VERSION "2.0"

NS_ :

BS_:

BU_: PCU NDR

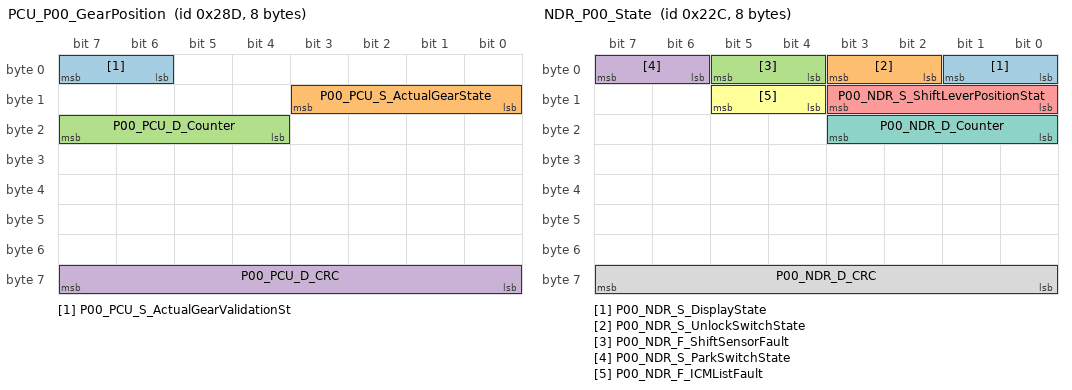
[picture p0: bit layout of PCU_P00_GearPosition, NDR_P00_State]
BO_ 653 PCU_P00_GearPosition: 8 PCU
 SG_ P00_PCU_S_ActualGearValidationSt : 6|2@1+ (1,0) [0|3] ""  PCU
 SG_ P00_PCU_S_ActualGearState : 8|4@1+ (1,0) [0|15] ""  PCU
 SG_ P00_PCU_D_Counter : 20|4@1+ (1,0) [0|15] ""  PCU
 SG_ P00_PCU_D_CRC : 56|8@1+ (1,0) [0|255] ""  PCU

BO_ 556 NDR_P00_State: 8 NDR
 SG_ P00_NDR_S_DisplayState : 0|2@1+ (1,0) [0|3] ""  NDR
 SG_ P00_NDR_S_UnlockSwitchState : 2|2@1+ (1,0) [0|3] ""  NDR
 SG_ P00_NDR_F_ShiftSensorFault : 4|2@1+ (1,0) [0|3] ""  NDR
 SG_ P00_NDR_S_ParkSwitchState : 6|2@1+ (1,0) [0|3] ""  NDR
 SG_ P00_NDR_S_ShiftLeverPositionStat : 8|4@1+ (1,0) [0|15] ""  NDR
 SG_ P00_NDR_F_ICMListFault : 12|2@1+ (1,0) [0|1] ""  NDR
 SG_ P00_NDR_D_Counter : 16|4@1+ (1,0) [0|15] ""  NDR
 SG_ P00_NDR_D_CRC : 56|8@1+ (1,0) [0|255] ""  NDR

BO_ 1174 PCU_P01_Authentication: 8 PCU
 SG_ P01_PCU_S_AuthenticationState : 0|8@1+ (1,0) [0|3] ""  PCU

CM_ BO_ 653 "Gear Position Message; Functional Type";
CM_ SG_ 653 P00_PCU_S_ActualGearValidationSt "Actual gear validation state";
CM_ SG_ 653 P00_PCU_S_ActualGearState "Actual gear position state";
CM_ SG_ 653 P00_PCU_D_Counter "Up counter (0-15)";
CM_ SG_ 653 P00_PCU_D_CRC "Message CRC for Integrity";
CM_ BO_ 556 "State Message to NDR; Functional Type";
CM_ SG_ 556 P00_NDR_S_DisplayState "Gear position display state";
CM_ SG_ 556 P00_NDR_S_UnlockSwitchState "Unlock switch state";
CM_ SG_ 556 P00_NDR_F_ShiftSensorFault "Shift sensor fault";
CM_ SG_ 556 P00_NDR_S_ParkSwitchState "Park switch state";
CM_ SG_ 556 P00_NDR_S_ShiftLeverPositionStat "Shift lever position state";
CM_ SG_ 556 P00_NDR_F_ICMListFault "Integrated Control Module (ICM) list fault";
CM_ SG_ 556 P00_NDR_D_Counter "Up counter (0-15)";
CM_ SG_ 556 P00_NDR_D_CRC "8 bit CRC";
CM_ BO_ 1174 "Authentication Message; Event Triggered";
CM_ SG_ 1174 P01_PCU_S_AuthenticationState "Authentication state";
BA_DEF_ BO_  "TXRX" ENUM  "TX","RX";
BA_DEF_ BO_  "J1939PgAppearanceOnBus" ENUM  "Default","CAN_Extended","CANFD_Extended";
BA_DEF_ BO_  "J1939CPgSendTimeout" INT -1 3600000;
BA_DEF_ BO_  "J1939CPgTOS" INT 0 7;
BA_DEF_ BU_  "J1939MultiPgSendTimeout" INT 0 3600000;
BA_DEF_ BU_  "J1939MultiPgSizeThreshold" INT 0 64;
BA_DEF_ BU_  "J1939MultiPgBroadcastType" ENUM  "FBFF","FEFF";
BA_DEF_ SG_  "SigType" ENUM  "Default","Range","RangeSigned","ASCII","Discrete","Control","ReferencePGN","DTC","StringDelimiter","StringLength","StringLengthControl","MessageCounter","MessageChecksum";
BA_DEF_ SG_  "GenSigILSupport" ENUM  "No","Yes";
BA_DEF_ SG_  "GenSigSendType" ENUM  "Cyclic","OnWrite","OnWriteWithRepetition","OnChange","OnChangeWithRepetition","IfActive","IfActiveWithRepetition","NoSigSendType";
BA_DEF_ SG_  "GenSigStartValue" INT 0 2147483647;
BA_DEF_ BO_  "GenMsgILSupport" ENUM  "No","Yes";
BA_DEF_ BU_  "NmStationAddress" INT 0 255;
BA_DEF_ BO_  "GenMsgSendType" ENUM  "cyclic","NotUsed","NotUsed","NotUsed","NotUsed","NotUsed","NotUsed","IfActive","noMsgSendType";
BA_DEF_ BO_  "GenMsgRequestable" INT 0 1;
BA_DEF_ BO_  "GenMsgCycleTime" INT 0 3600000;
BA_DEF_ SG_  "SPN" INT 0 524287;
BA_DEF_  "DBName" STRING ;
BA_DEF_  "BusType" STRING ;
BA_DEF_  "ProtocolType" STRING ;
BA_DEF_ BO_  "VFrameFormat" ENUM  "StandardCAN","ExtendedCAN","reserved","J1939PG","reserved","reserved","reserved","reserved","reserved","reserved","reserved","reserved","reserved","reserved","StandardCAN_FD","ExtendedCAN_FD";
BA_DEF_ SG_  "SystemSignalLongSymbol" STRING ;
BA_DEF_DEF_  "TXRX" "TX";
BA_DEF_DEF_  "J1939PgAppearanceOnBus" "Default";
BA_DEF_DEF_  "J1939CPgSendTimeout" -1;
BA_DEF_DEF_  "J1939CPgTOS" 2;
BA_DEF_DEF_  "J1939MultiPgSendTimeout" 2;
BA_DEF_DEF_  "J1939MultiPgSizeThreshold" 56;
BA_DEF_DEF_  "J1939MultiPgBroadcastType" "FBFF";
BA_DEF_DEF_  "SigType" "Default";
BA_DEF_DEF_  "GenSigILSupport" "Yes";
BA_DEF_DEF_  "GenSigSendType" "NoSigSendType";
BA_DEF_DEF_  "GenSigStartValue" 0;
BA_DEF_DEF_  "GenMsgILSupport" "Yes";
BA_DEF_DEF_  "NmStationAddress" 254;
BA_DEF_DEF_  "GenMsgSendType" "noMsgSendType";
BA_DEF_DEF_  "GenMsgRequestable" 1;
BA_DEF_DEF_  "GenMsgCycleTime" 0;
BA_DEF_DEF_  "SPN" 0;
BA_DEF_DEF_  "DBName" "";
BA_DEF_DEF_  "BusType" "CAN";
BA_DEF_DEF_  "ProtocolType" "J1939";
BA_DEF_DEF_  "VFrameFormat" "J1939PG";
BA_DEF_DEF_  "SystemSignalLongSymbol" "";
BA_ "DBName" "NDR";
BA_ "NmStationAddress" BU_ PCU 1;
BA_ "NmStationAddress" BU_ NDR 26;
BA_ "GenMsgSendType" BO_ 653 0;
BA_ "GenMsgCycleTime" BO_ 653 10;
BA_ "VFrameFormat" BO_ 653 0;
BA_ "GenMsgSendType" BO_ 556 0;
BA_ "GenMsgCycleTime" BO_ 556 10;
BA_ "VFrameFormat" BO_ 556 0;
BA_ "TXRX" BO_ 556 1;
BA_ "GenMsgSendType" BO_ 1174 7;
BA_ "VFrameFormat" BO_ 1174 0;
BA_ "GenSigSendType" SG_ 653 P00_PCU_S_ActualGearValidationSt 0;
BA_ "SystemSignalLongSymbol" SG_ 653 P00_PCU_S_ActualGearValidationSt "P00_PCU_S_ActualGearValidationState";
BA_ "GenSigSendType" SG_ 653 P00_PCU_S_ActualGearState 0;
BA_ "SPN" SG_ 653 P00_PCU_S_ActualGearState 2450;
BA_ "GenSigSendType" SG_ 556 P00_NDR_S_DisplayState 0;
BA_ "GenSigSendType" SG_ 556 P00_NDR_S_UnlockSwitchState 0;
BA_ "GenSigSendType" SG_ 556 P00_NDR_F_ShiftSensorFault 0;
BA_ "GenSigSendType" SG_ 556 P00_NDR_S_ParkSwitchState 0;
BA_ "GenSigSendType" SG_ 556 P00_NDR_S_ShiftLeverPositionStat 0;
BA_ "SystemSignalLongSymbol" SG_ 556 P00_NDR_S_ShiftLeverPositionStat "P00_NDR_S_ShiftLeverPositionState";
BA_ "GenSigSendType" SG_ 556 P00_NDR_F_ICMListFault 0;
BA_ "GenSigSendType" SG_ 556 P00_NDR_D_Counter 0;
BA_ "GenSigSendType" SG_ 556 P00_NDR_D_CRC 0;
BA_ "GenSigStartValue" SG_ 1174 P01_PCU_S_AuthenticationState 1;
BA_ "GenSigSendType" SG_ 1174 P01_PCU_S_AuthenticationState 0;
VAL_ 653 P00_PCU_S_ActualGearValidationSt 3 "SNA" 1 "Valid" 0 "Invalid" ;
VAL_ 653 P00_PCU_S_ActualGearState 15 "SNA" 14 "Fault" 4 "S" 3 "R" 2 "D" 1 "N" 0 "P" ;
VAL_ 556 P00_NDR_S_DisplayState 2 "Reserved" 3 "Invalid" 1 "Display fault" 0 "Display OK" ;
VAL_ 556 P00_NDR_S_UnlockSwitchState 2 "Reserved" 3 "Invalid" 1 "Pressed" 0 "Not pressed" ;
VAL_ 556 P00_NDR_F_ShiftSensorFault 3 "D/M sensor fault" 2 "Full fault (for P/R/N/D)" 1 "Single fault (for P/R/N/D)" 0 "No fault" ;
VAL_ 556 P00_NDR_S_ParkSwitchState 2 "Reserved" 3 "Invalid" 1 "Pressed" 0 "Not pressed" ;
VAL_ 556 P00_NDR_S_ShiftLeverPositionStat 10 "Reserved" 1 "Reserved" 15 "Invalid" 9 "Shifter not initialized (not learned)" 8 "M+" 7 "M-" 6 "Manual/Sport" 5 "Backward twice" 4 "Backward once" 3 "Forward once" 2 "Forward twice" 0 "Zero" ;
VAL_ 556 P00_NDR_F_ICMListFault 1 "Fault" 0 "No fault" ;
VAL_ 1174 P01_PCU_S_AuthenticationState 3 "Reserved" 2 "Fault" 1 "Success" 0 "Default" ;
